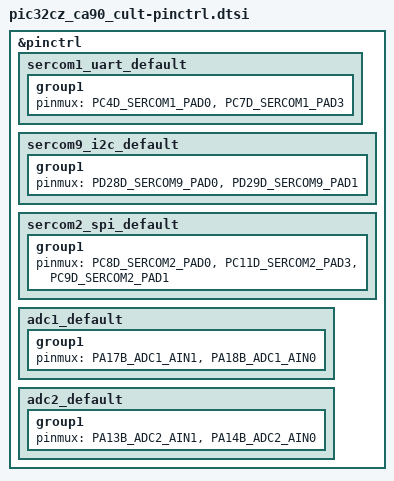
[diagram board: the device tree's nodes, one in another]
/*
 * Copyright (c) 2026 Microchip Technology Inc.
 *
 * SPDX-License-Identifier: Apache-2.0
 */

#include <dt-bindings/pic32c/pic32cz_ca/pic32cz_ca90/pic32cz8110ca90208-pinctrl.h>

&pinctrl {
	sercom1_uart_default: sercom1_uart_default {
		group1 {
			pinmux = <PC4D_SERCOM1_PAD0>,
				 <PC7D_SERCOM1_PAD3>;
		};
	};

	sercom9_i2c_default: sercom9_i2c_default {
		group1 {
			pinmux = <PD28D_SERCOM9_PAD0>,  /* SDA */
				 <PD29D_SERCOM9_PAD1>;  /* SCL */
		};
	};

	sercom2_spi_default: sercom2_spi_default {
		group1 {
			pinmux = <PC8D_SERCOM2_PAD0>,   /* MOSI */
				 <PC11D_SERCOM2_PAD3>,  /* MISO */
				 <PC9D_SERCOM2_PAD1>;   /* SCK  */
		};
	};

	adc1_default: adc1_default {
		group1 {
			pinmux = <PA17B_ADC1_AIN1>,	/* PA17, ADC1 negative (differential) */
				 <PA18B_ADC1_AIN0>;	/* PA18, ADC1 positive (differential) */
		};
	};

	adc2_default: adc2_default {
		group1 {
			pinmux = <PA13B_ADC2_AIN1>,	/* PA13, ADC1 negative (differential) */
				 <PA14B_ADC2_AIN0>;	/* PA14, ADC1 positive (differential) */
		};
	};
};
